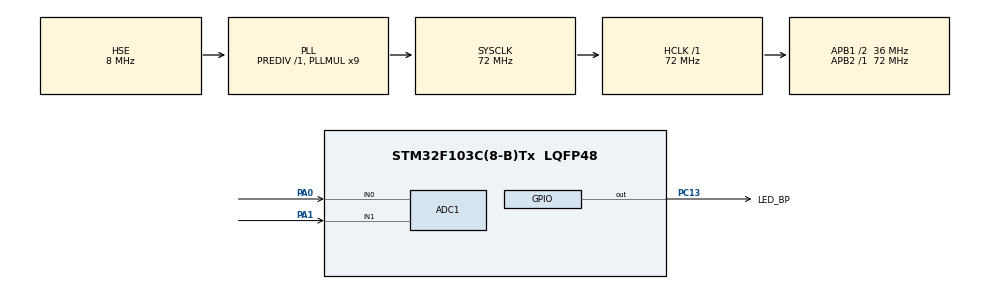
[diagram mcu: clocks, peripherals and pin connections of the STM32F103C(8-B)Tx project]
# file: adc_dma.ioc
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Mcu.Family=STM32F1
RCC.PLLSourceVirtual=RCC_PLLSOURCE_HSE
PC15-OSC32_OUT.Mode=LSE-External-Oscillator
NVIC.ADC1_2_IRQn=true\:0\:0\:false\:false\:true\:true\:true
Dma.ADC1.0.Instance=DMA1_Channel1
PD1-OSC_OUT.Mode=HSE-External-Oscillator
ADC1.ContinuousConvMode=DISABLE
ADC1.SamplingTime-6\#ChannelRegularConversion=ADC_SAMPLETIME_239CYCLES_5
PC13-TAMPER-RTC.Signal=GPIO_Output
PD0-OSC_IN.Signal=RCC_OSC_IN
RCC.APB1CLKDivider=RCC_HCLK_DIV2
PC14-OSC32_IN.Signal=RCC_OSC32_IN
RCC.SYSCLKSource=RCC_SYSCLKSOURCE_PLLCLK
ProjectManager.StackSize=0x400
PA0-WKUP.Signal=ADCx_IN0
ADC1.Channel-7\#ChannelRegularConversion=ADC_CHANNEL_1
PD1-OSC_OUT.Signal=RCC_OSC_OUT
RCC.ADCPresc=RCC_ADCPCLK2_DIV6
PA13.Signal=SYS_JTMS-SWDIO
Dma.ADC1.0.PeriphDataAlignment=DMA_PDATAALIGN_HALFWORD
ProjectManager.TargetToolchain=STM32CubeIDE
Dma.ADC1.0.Mode=DMA_CIRCULAR
RCC.HCLKFreq_Value=72000000
Dma.ADC1.0.Priority=DMA_PRIORITY_LOW
RCC.APB2TimFreq_Value=72000000
TIM3.Period=10000-1
Dma.ADC1.0.Direction=DMA_PERIPH_TO_MEMORY
RCC.USBFreq_Value=72000000
PC15-OSC32_OUT.Signal=RCC_OSC32_OUT
Dma.ADC1.0.MemDataAlignment=DMA_MDATAALIGN_HALFWORD
PA1.Signal=ADCx_IN1
RCC.AHBFreq_Value=72000000
PD0-OSC_IN.Mode=HSE-External-Oscillator
board=custom
PC13-TAMPER-RTC.GPIO_Label=LED_BP
RCC.PLLMUL=RCC_PLL_MUL9
ADC1.Channel-6\#ChannelRegularConversion=ADC_CHANNEL_0
RCC.APB2Freq_Value=72000000
PC14-OSC32_IN.Mode=LSE-External-Oscillator
PA14.Mode=Serial_Wire
TIM3.Prescaler=72-1
Dma.ADC1.0.PeriphInc=DMA_PINC_DISABLE
SH.ADCx_IN0.0=ADC1_IN0,IN0
ADC1.NbrOfConversion=2
PA13.Mode=Serial_Wire
Mcu.Name=STM32F103C(8-B)Tx
ADC1.ExternalTrigConv=ADC_EXTERNALTRIGCONV_T3_TRGO
RCC.SYSCLKFreq_VALUE=72000000
Mcu.Package=LQFP48
ADC1.master=1
PA14.Signal=SYS_JTCK-SWCLK
Dma.ADC1.0.MemInc=DMA_MINC_ENABLE
ProjectManager.HeapSize=0x200
ADC1.Rank-7\#ChannelRegularConversion=2
NVIC.PriorityGroup=NVIC_PRIORITYGROUP_4
ADC1.NbrOfConversionFlag=1
SH.ADCx_IN1.0=ADC1_IN1,IN1
RCC.APB1TimFreq_Value=72000000
ADC1.SamplingTime-7\#ChannelRegularConversion=ADC_SAMPLETIME_1CYCLE_5
NVIC.DMA1_Channel1_IRQn=true\:0\:0\:false\:false\:true\:false\:true
TIM3.TIM_MasterOutputTrigger=TIM_TRGO_UPDATE
ADC1.Rank-6\#ChannelRegularConversion=1
Dma.Request0=ADC1
RCC.APB1Freq_Value=36000000
VP_TIM3_VS_ClockSourceINT.Mode=Internal

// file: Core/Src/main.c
/* USER CODE BEGIN Header */
/**
 ******************************************************************************
 * @file           : main.c
 * @brief          : Main program body
 ******************************************************************************
 * @attention
 *
 * <h2><center>&copy; Copyright (c) 2021 STMicroelectronics.
 * All rights reserved.</center></h2>
 *
 * This software component is licensed by ST under BSD 3-Clause license,
 * the "License"; You may not use this file except in compliance with the
 * License. You may obtain a copy of the License at:
 *                        opensource.org/licenses/BSD-3-Clause
 *
 ******************************************************************************
 */
/* USER CODE END Header */
#include "main.h"

/* USER CODE BEGIN PD */
#define ADC_N_CHANNELS      2
#define ADC_SAMPLES_PER_CH  1
#define ADC_BUFFER_LEN      ADC_N_CHANNELS * ADC_SAMPLES_PER_CH
/* USER CODE END PD */

ADC_HandleTypeDef hadc1;
DMA_HandleTypeDef hdma_adc1;

TIM_HandleTypeDef htim3;

/* USER CODE BEGIN PV */
static uint16_t adc_values[ADC_BUFFER_LEN];
static uint8_t  adc_done;
/* USER CODE END PV */

void SystemClock_Config(void);
static void MX_GPIO_Init(void);
static void MX_DMA_Init(void);
static void MX_ADC1_Init(void);
static void MX_TIM3_Init(void);

/* USER CODE BEGIN 0 */

/**
 * @brief  Conversion complete callback in non-blocking mode
 * @param  hadc: ADC handle
 * @retval None
 */
void HAL_ADC_ConvCpltCallback(ADC_HandleTypeDef* hadc)
{
	adc_done = 1;
}

/* USER CODE END 0 */

int main(void)
{

	/* MCU Configuration--------------------------------------------------------*/

	/* Reset of all peripherals, Initializes the Flash interface and the Systick. */
	HAL_Init();

	/* Configure the system clock */
	SystemClock_Config();

	/* Initialize all configured peripherals */
	MX_GPIO_Init();
	MX_DMA_Init();
	MX_ADC1_Init();
	MX_TIM3_Init();

	/* Infinite loop */
	/* USER CODE BEGIN WHILE */

	/* Perform an ADC self-calibration to reduce accuracy errors */
	HAL_ADCEx_Calibration_Start(&hadc1);

	/* Start a new ADC conversion every 10 ms (launched by Timer 3) */
	HAL_TIM_Base_Start(&htim3);
	HAL_ADC_Start_DMA(&hadc1, (uint32_t *)adc_values, ADC_BUFFER_LEN);

	while (1)
	{
		/* Process the ADC conversion results when they are ready */
		if (adc_done) {
			adc_done = 0;
			/* ... */
		}

		__WFI();

		/* USER CODE END WHILE */

	}
}

void SystemClock_Config(void)
{
	RCC_OscInitTypeDef RCC_OscInitStruct = {0};
	RCC_ClkInitTypeDef RCC_ClkInitStruct = {0};
	RCC_PeriphCLKInitTypeDef PeriphClkInit = {0};

	/** Initializes the RCC Oscillators according to the specified parameters
	 * in the RCC_OscInitTypeDef structure.
	 */
	RCC_OscInitStruct.OscillatorType = RCC_OSCILLATORTYPE_HSE;
	RCC_OscInitStruct.HSEState = RCC_HSE_ON;
	RCC_OscInitStruct.HSEPredivValue = RCC_HSE_PREDIV_DIV1;
	RCC_OscInitStruct.HSIState = RCC_HSI_ON;
	RCC_OscInitStruct.PLL.PLLState = RCC_PLL_ON;
	RCC_OscInitStruct.PLL.PLLSource = RCC_PLLSOURCE_HSE;
	RCC_OscInitStruct.PLL.PLLMUL = RCC_PLL_MUL9;
	if (HAL_RCC_OscConfig(&RCC_OscInitStruct) != HAL_OK)
	{
		Error_Handler();
	}
	/** Initializes the CPU, AHB and APB buses clocks
	 */
	RCC_ClkInitStruct.ClockType = RCC_CLOCKTYPE_HCLK|RCC_CLOCKTYPE_SYSCLK
			|RCC_CLOCKTYPE_PCLK1|RCC_CLOCKTYPE_PCLK2;
	RCC_ClkInitStruct.SYSCLKSource = RCC_SYSCLKSOURCE_PLLCLK;
	RCC_ClkInitStruct.AHBCLKDivider = RCC_SYSCLK_DIV1;
	RCC_ClkInitStruct.APB1CLKDivider = RCC_HCLK_DIV2;
	RCC_ClkInitStruct.APB2CLKDivider = RCC_HCLK_DIV1;

	if (HAL_RCC_ClockConfig(&RCC_ClkInitStruct, FLASH_LATENCY_2) != HAL_OK)
	{
		Error_Handler();
	}
	PeriphClkInit.PeriphClockSelection = RCC_PERIPHCLK_ADC;
	PeriphClkInit.AdcClockSelection = RCC_ADCPCLK2_DIV6;
	if (HAL_RCCEx_PeriphCLKConfig(&PeriphClkInit) != HAL_OK)
	{
		Error_Handler();
	}
}

static void MX_ADC1_Init(void)
{

	ADC_ChannelConfTypeDef sConfig = {0};

	/** Common config
	 */
	hadc1.Instance = ADC1;
	hadc1.Init.ScanConvMode = ADC_SCAN_ENABLE;
	hadc1.Init.ContinuousConvMode = DISABLE;
	hadc1.Init.DiscontinuousConvMode = DISABLE;
	hadc1.Init.ExternalTrigConv = ADC_EXTERNALTRIGCONV_T3_TRGO;
	hadc1.Init.DataAlign = ADC_DATAALIGN_RIGHT;
	hadc1.Init.NbrOfConversion = 2;
	if (HAL_ADC_Init(&hadc1) != HAL_OK)
	{
		Error_Handler();
	}
	/** Configure Regular Channel
	 */
	sConfig.Channel = ADC_CHANNEL_0;
	sConfig.Rank = ADC_REGULAR_RANK_1;
	sConfig.SamplingTime = ADC_SAMPLETIME_239CYCLES_5;
	if (HAL_ADC_ConfigChannel(&hadc1, &sConfig) != HAL_OK)
	{
		Error_Handler();
	}
	/** Configure Regular Channel
	 */
	sConfig.Channel = ADC_CHANNEL_1;
	sConfig.Rank = ADC_REGULAR_RANK_2;
	sConfig.SamplingTime = ADC_SAMPLETIME_1CYCLE_5;
	if (HAL_ADC_ConfigChannel(&hadc1, &sConfig) != HAL_OK)
	{
		Error_Handler();
	}

}

static void MX_TIM3_Init(void)
{

	TIM_ClockConfigTypeDef sClockSourceConfig = {0};
	TIM_MasterConfigTypeDef sMasterConfig = {0};

	htim3.Instance = TIM3;
	htim3.Init.Prescaler = 72-1;
	htim3.Init.CounterMode = TIM_COUNTERMODE_UP;
	htim3.Init.Period = 10000-1;
	htim3.Init.ClockDivision = TIM_CLOCKDIVISION_DIV1;
	htim3.Init.AutoReloadPreload = TIM_AUTORELOAD_PRELOAD_DISABLE;
	if (HAL_TIM_Base_Init(&htim3) != HAL_OK)
	{
		Error_Handler();
	}
	sClockSourceConfig.ClockSource = TIM_CLOCKSOURCE_INTERNAL;
	if (HAL_TIM_ConfigClockSource(&htim3, &sClockSourceConfig) != HAL_OK)
	{
		Error_Handler();
	}
	sMasterConfig.MasterOutputTrigger = TIM_TRGO_UPDATE;
	sMasterConfig.MasterSlaveMode = TIM_MASTERSLAVEMODE_DISABLE;
	if (HAL_TIMEx_MasterConfigSynchronization(&htim3, &sMasterConfig) != HAL_OK)
	{
		Error_Handler();
	}

}

static void MX_DMA_Init(void)
{

	/* DMA controller clock enable */
	__HAL_RCC_DMA1_CLK_ENABLE();

	/* DMA interrupt init */
	/* DMA1_Channel1_IRQn interrupt configuration */
	HAL_NVIC_SetPriority(DMA1_Channel1_IRQn, 0, 0);
	HAL_NVIC_EnableIRQ(DMA1_Channel1_IRQn);

}

static void MX_GPIO_Init(void)
{
	GPIO_InitTypeDef GPIO_InitStruct = {0};

	/* GPIO Ports Clock Enable */
	__HAL_RCC_GPIOC_CLK_ENABLE();
	__HAL_RCC_GPIOD_CLK_ENABLE();
	__HAL_RCC_GPIOA_CLK_ENABLE();

	/*Configure GPIO pin Output Level */
	HAL_GPIO_WritePin(LED_BP_GPIO_Port, LED_BP_Pin, GPIO_PIN_RESET);

	/*Configure GPIO pin : LED_BP_Pin */
	GPIO_InitStruct.Pin = LED_BP_Pin;
	GPIO_InitStruct.Mode = GPIO_MODE_OUTPUT_PP;
	GPIO_InitStruct.Pull = GPIO_NOPULL;
	GPIO_InitStruct.Speed = GPIO_SPEED_FREQ_LOW;
	HAL_GPIO_Init(LED_BP_GPIO_Port, &GPIO_InitStruct);

}

void Error_Handler(void)
{
	__disable_irq();
	while (1)
	{
	}
}

/************************ (C) COPYRIGHT STMicroelectronics *****END OF FILE****/
